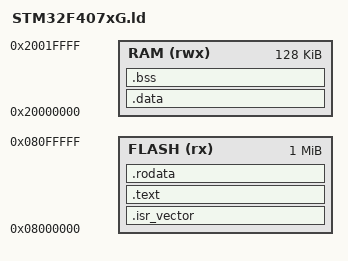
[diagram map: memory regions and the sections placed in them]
/* Entry Point */
ENTRY(Reset_Handler)

MEMORY
{
  FLASH (rx)  : ORIGIN = 0x08000000, LENGTH = 1024K
  RAM   (rwx) : ORIGIN = 0x20000000, LENGTH = 128K
}

/* Stack top derived from RAM size */
_estack = ORIGIN(RAM) + LENGTH(RAM);

SECTIONS
{
  .isr_vector :
  {
    . = ALIGN(4);
    KEEP(*(.isr_vector))
    . = ALIGN(4);
  } >FLASH

  .text :
  {
    . = ALIGN(4);
    *(.text)
    *(.text*)
    . = ALIGN(4);
    _etext = .;
  } >FLASH

  .rodata :
  {
    . = ALIGN(4);
    *(.rodata)
    *(.rodata*)
    . = ALIGN(4);
  } >FLASH

  /* 用于启动代码搬运 .data */
  _sidata = LOADADDR(.data);

  .data : AT (ADDR(.text) + SIZEOF(.text) + SIZEOF(.rodata))
  {
    . = ALIGN(4);
    _sdata = .;
    *(.data)
    *(.data*)
    . = ALIGN(4);
    _edata = .;
  } >RAM

  .bss :
  {
    . = ALIGN(4);
    _sbss = .;
    __bss_start__ = _sbss;
    *(.bss)
    *(.bss*)
    *(COMMON)
    . = ALIGN(4);
    _ebss = .;
    __bss_end__ = _ebss;
  } >RAM
}
